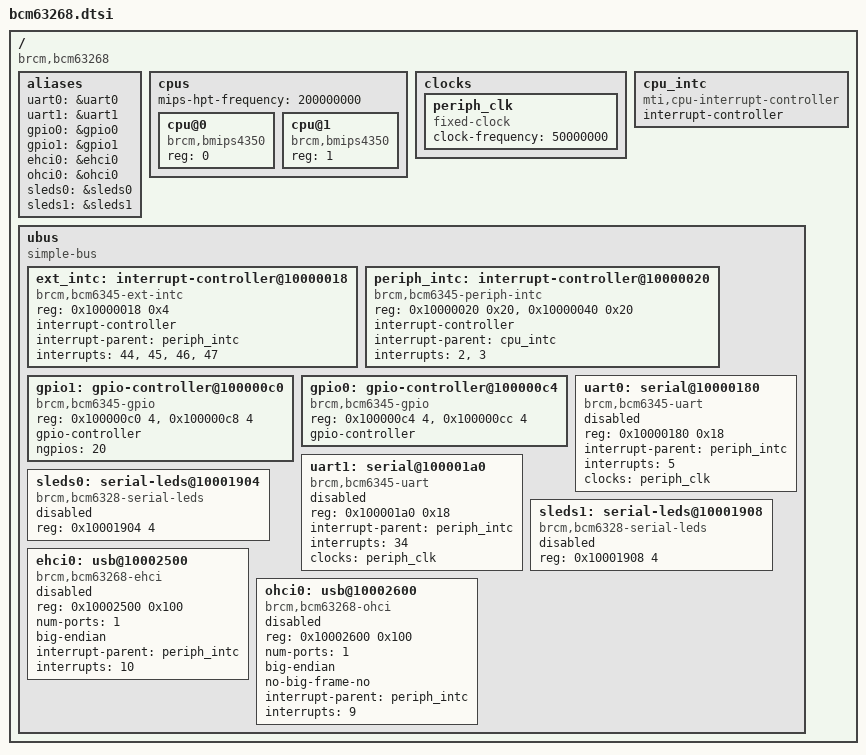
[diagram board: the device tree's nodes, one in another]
/ {
	#address-cells = <1>;
	#size-cells = <1>;
	compatible = "brcm,bcm63268";

	aliases {
		uart0 = &uart0;
		uart1 = &uart1;
		gpio0 = &gpio0;
		gpio1 = &gpio1;
		ehci0 = &ehci0;
		ohci0 = &ohci0;
		sleds0 = &sleds0;
		sleds1 = &sleds1;
	};

	cpus {
		#address-cells = <1>;
		#size-cells = <0>;

		mips-hpt-frequency = <200000000>;

		cpu@0 {
			compatible = "brcm,bmips4350";
			device_type = "cpu";
			reg = <0>;
		};

		cpu@1 {
			compatible = "brcm,bmips4350";
			device_type = "cpu";
			reg = <1>;
		};
	};

	clocks {
		periph_clk: periph_clk {
			compatible = "fixed-clock";
			#clock-cells = <0>;
			clock-frequency = <50000000>;
		};
	};

	cpu_intc: cpu_intc {
		#address-cells = <0>;
		compatible = "mti,cpu-interrupt-controller";

		interrupt-controller;
		#interrupt-cells = <1>;
	};

	ubus {
		#address-cells = <1>;
		#size-cells = <1>;

		compatible = "simple-bus";
		ranges;

		ext_intc: interrupt-controller@10000018 {
			compatible = "brcm,bcm6345-ext-intc";
			reg = <0x10000018 0x4>;

			interrupt-controller;
			#interrupt-cells = <2>;

			interrupt-parent = <&periph_intc>;
			interrupts = <44>, <45>, <46>, <47>;
		};

		periph_intc: interrupt-controller@10000020 {
			compatible = "brcm,bcm6345-periph-intc";
			reg = <0x10000020 0x20>,
			      <0x10000040 0x20>;

			interrupt-controller;
			#interrupt-cells = <1>;

			interrupt-parent = <&cpu_intc>;
			interrupts = <2>, <3>;
		};

		gpio1: gpio-controller@100000c0 {
			compatible = "brcm,bcm6345-gpio";
			reg = <0x100000c0 4>, <0x100000c8 4>;

			gpio-controller;
			#gpio-cells = <2>;

			ngpios = <20>;
		};

		gpio0: gpio-controller@100000c4 {
			compatible = "brcm,bcm6345-gpio";
			reg = <0x100000c4 4>, <0x100000cc 4>;

			gpio-controller;
			#gpio-cells = <2>;
		};

		uart0: serial@10000180 {
			compatible = "brcm,bcm6345-uart";
			reg = <0x10000180 0x18>;
			interrupt-parent = <&periph_intc>;
			interrupts = <5>;
			clocks = <&periph_clk>;
			status = "disabled";
		};

		uart1: serial@100001a0 {
			compatible = "brcm,bcm6345-uart";
			reg = <0x100001a0 0x18>;
			interrupt-parent = <&periph_intc>;
			interrupts = <34>;
			clocks = <&periph_clk>;
			status = "disabled";
		};

		sleds0: serial-leds@10001904 {
			compatible = "brcm,bcm6328-serial-leds";
			reg = <0x10001904 4>;
			reg-names = "dat";

			status = "disabled";
		};

		sleds1: serial-leds@10001908 {
			compatible = "brcm,bcm6328-serial-leds";
			reg = <0x10001908 4>;
			reg-names = "dat";

			status = "disabled";
		};

		ehci0: usb@10002500 {
			compatible = "brcm,bcm63268-ehci", "generic-ehci";
			reg = <0x10002500 0x100>;
			num-ports = <1>;
			big-endian;
			interrupt-parent = <&periph_intc>;
			interrupts = <10>;
			status = "disabled";
		};

		ohci0: usb@10002600 {
			compatible = "brcm,bcm63268-ohci", "generic-ohci";
			reg = <0x10002600 0x100>;
			num-ports = <1>;
			big-endian;
			no-big-frame-no;
			interrupt-parent = <&periph_intc>;
			interrupts = <9>;
			status = "disabled";
		};
	};
};
